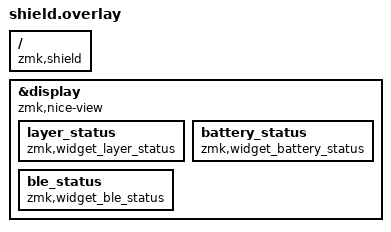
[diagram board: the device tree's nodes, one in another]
/ {
  compatible = "zmk,shield";
};

&display {
  compatible = "zmk,nice-view";

  layer_status {
    compatible = "zmk,widget_layer_status";
    status = "okay";
  };

  battery_status {
    compatible = "zmk,widget_battery_status";
    status = "okay";
  };

  ble_status {
    compatible = "zmk,widget_ble_status";
    status = "okay";
  };
};
